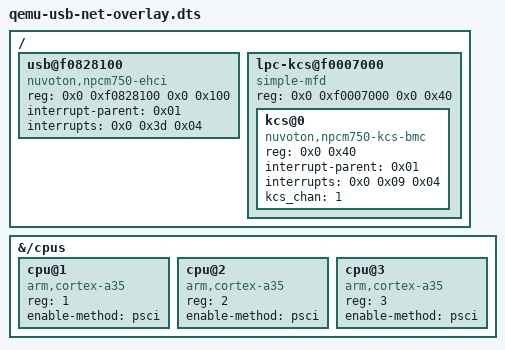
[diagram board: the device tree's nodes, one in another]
/dts-v1/;
/plugin/;

/ {
	fragment@0 {
		target-path = "/";

		__overlay__ {
			#address-cells = <2>;
			#size-cells = <2>;

			usb@f0828100 {
				compatible = "nuvoton,npcm750-ehci";
				reg = <0x0 0xf0828100 0x0 0x100>;
				interrupt-parent = <0x01>;
				interrupts = <0x0 0x3d 0x04>;
				status = "okay";
			};

			lpc-kcs@f0007000 {
				compatible = "simple-mfd", "syscon";
				reg = <0x0 0xf0007000 0x0 0x40>;
				#address-cells = <1>;
				#size-cells = <1>;
				ranges = <0x0 0x0 0xf0007000 0x40>;

				kcs@0 {
					compatible = "nuvoton,npcm750-kcs-bmc";
					reg = <0x0 0x40>;
					interrupt-parent = <0x01>;
					interrupts = <0x0 0x09 0x04>;
					kcs_chan = <1>;
					status = "okay";
				};
			};
		};
	};

	fragment@1 {
		target-path = "/cpus";

		__overlay__ {
			#address-cells = <1>;
			#size-cells = <0>;

			cpu@1 {
				device_type = "cpu";
				compatible = "arm,cortex-a35";
				reg = <1>;
				enable-method = "psci";
			};

			cpu@2 {
				device_type = "cpu";
				compatible = "arm,cortex-a35";
				reg = <2>;
				enable-method = "psci";
			};

			cpu@3 {
				device_type = "cpu";
				compatible = "arm,cortex-a35";
				reg = <3>;
				enable-method = "psci";
			};
		};
	};
};
